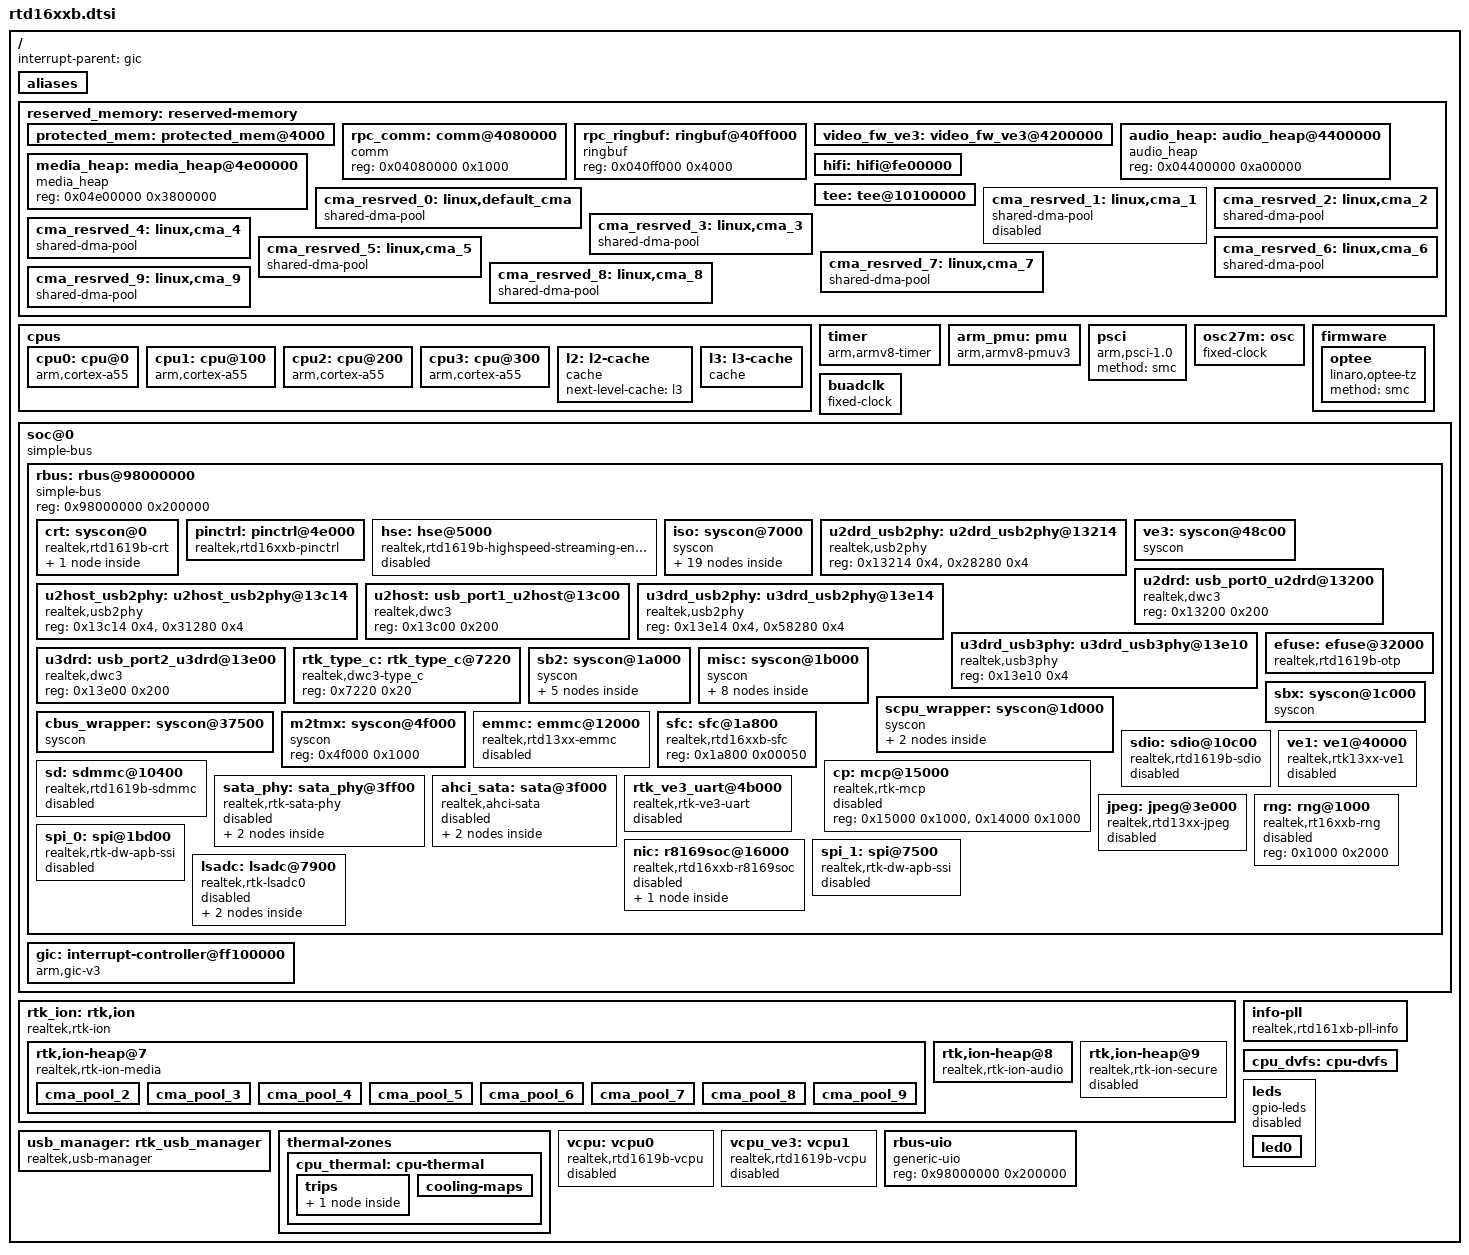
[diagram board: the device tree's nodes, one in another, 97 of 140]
// SPDX-License-Identifier: (GPL-2.0-or-later OR BSD-2-Clause)
/*
 * Realtek RTD1619b SoC family
 *
 * Copyright (c) 2020 Realtek Semiconductor Corp.
 */

#include <dt-bindings/interrupt-controller/arm-gic.h>
#include <dt-bindings/interrupt-controller/irq.h>
#include <dt-bindings/gpio/gpio.h>
#include <dt-bindings/clock/rtd1619b-clk.h>
#include <dt-bindings/reset/rtd1619b-reset.h>
#include <dt-bindings/power/rtd1619b-power.h>
#include <dt-bindings/soc/realtek,mem-flag.h>
#include <dt-bindings/leds/common.h>

/ {
	interrupt-parent = <&gic>;
	#address-cells = <1>;
	#size-cells = <1>;

	aliases {
		serial0 = &uart0;
		serial1 = &uart1;
		serial2 = &uart2;
		i2c0 = &i2c_0;
		i2c1 = &i2c_1;
		i2c3 = &i2c_3;
		i2c4 = &i2c_4;
		i2c5 = &i2c_5;
		watchdog0 = &watchdog;
	};

	reserved_memory: reserved-memory {
		#address-cells = <1>;
		#size-cells = <1>;
		ranges;

		protected_mem: protected_mem@4000 {
			reg = <0x00004000 0x1000000>;
			no-map;
		};

		rpc_comm: comm@4080000 {
			compatible = "comm";
			reg = <0x04080000 0x1000>;
		};

		rpc_ringbuf: ringbuf@40ff000 {
			compatible = "ringbuf";
			reg = <0x040ff000 0x4000>;
		};

		video_fw_ve3: video_fw_ve3@4200000 {
			reg = <0x04200000 0x200000>;
			no-map;
		};

		audio_heap: audio_heap@4400000 {
			compatible = "audio_heap";
			reg = <0x04400000 0xa00000>;
		};

		media_heap: media_heap@4e00000 {
			compatible = "media_heap";
			reg = <0x04e00000 0x3800000>;
		};

		hifi: hifi@fe00000 {
			reg = <0x0fe00000 0x200000>;
			no-map;
		};

		tee: tee@10100000 {
			reg = <0x11000000 0x03200000>;
			no-map;
		};

		cma_resrved_0:linux,default_cma {
			compatible = "shared-dma-pool";
			size = <0x02000000>;
			alignment = <0x01000000>;
			linux,cma-default;
			linux,contiguous-region;
			reusable;
		};

		cma_resrved_1:linux,cma_1 {
			compatible = "shared-dma-pool";
			size = <0x02000000>;
			alloc-ranges=<0x14200000 0x0be00000>;
			linux,contiguous-region;
			reusable;
			status = "disabled";
		};

		cma_resrved_2:linux,cma_2 {
			compatible = "shared-dma-pool";
			size = <0x08000000>;
			alloc-ranges=<0x00000000 0x60000000>;
			linux,contiguous-region;
			reusable;
		};

		cma_resrved_3:linux,cma_3 {
			compatible = "shared-dma-pool";
			size = <0x10000000>;
			alignment = <0x01000000>;
			linux,contiguous-region;
			reusable;
		};

		cma_resrved_4:linux,cma_4 {
			compatible = "shared-dma-pool";
			size = <0x02000000>;
			alignment = <0x01000000>;
			linux,contiguous-region;
			reusable;
		};

		cma_resrved_5:linux,cma_5 {
			compatible = "shared-dma-pool";
			size = <0x01000000>;
			alignment = <0x01000000>;
			alloc-ranges=<0x00000000 0x60000000>;
			linux,contiguous-region;
			reusable;
		};

		cma_resrved_6:linux,cma_6 {
			compatible = "shared-dma-pool";
			size = <0x02000000>;
			alignment = <0x01000000>;
			alloc-ranges=<0x00000000 0x60000000>;
			linux,contiguous-region;
			reusable;
		};

		cma_resrved_7:linux,cma_7 {
			compatible = "shared-dma-pool";
			size = <0x01000000>;
			alignment = <0x01000000>;
			alloc-ranges=<0x00000000 0x60000000>;
			linux,contiguous-region;
			reusable;
		};

		cma_resrved_8:linux,cma_8 {
			compatible = "shared-dma-pool";
			size = <0x06000000>;
			alignment = <0x01000000>;
			alloc-ranges=<0x00000000 0x60000000>;
			linux,contiguous-region;
			reusable;
		};

		cma_resrved_9:linux,cma_9 {
			compatible = "shared-dma-pool";
			reusable;
			size = <0x04000000>;
			alignment = <0x01000000>;
			linux,contiguous-region;
			alloc-ranges=<0x00000000 0x60000000>;
		};
	};

	cpus {
		#address-cells = <1>;
		#size-cells = <0>;

		cpu0: cpu@0 {
			device_type = "cpu";
			compatible = "arm,cortex-a55";
			reg = <0x0>;
			enable-method = "psci";
			next-level-cache = <&l2>;
		};

		cpu1: cpu@100 {
			device_type = "cpu";
			compatible = "arm,cortex-a55";
			reg = <0x100>;
			enable-method = "psci";
			next-level-cache = <&l2>;
		};

		cpu2: cpu@200 {
			device_type = "cpu";
			compatible = "arm,cortex-a55";
			reg = <0x200>;
			enable-method = "psci";
			next-level-cache = <&l2>;
		};

		cpu3: cpu@300 {
			device_type = "cpu";
			compatible = "arm,cortex-a55";
			reg = <0x300>;
			enable-method = "psci";
			next-level-cache = <&l2>;
		};

		l2: l2-cache {
			compatible = "cache";
			next-level-cache = <&l3>;

		};

		l3: l3-cache {
			compatible = "cache";
		};
	};

	timer {
		compatible = "arm,armv8-timer";
		interrupts = <GIC_PPI 13 IRQ_TYPE_LEVEL_LOW>,
			     <GIC_PPI 14 IRQ_TYPE_LEVEL_LOW>,
			     <GIC_PPI 11 IRQ_TYPE_LEVEL_LOW>,
			     <GIC_PPI 10 IRQ_TYPE_LEVEL_LOW>,
			     <GIC_PPI 9 IRQ_TYPE_LEVEL_LOW>;
	};

	arm_pmu: pmu {
		compatible = "arm,armv8-pmuv3";
		interrupts = <GIC_PPI 7 IRQ_TYPE_LEVEL_LOW>;
		interrupt-affinity = <&cpu0>, <&cpu1>, <&cpu2>, <&cpu3>;
	};

	psci: psci {
		compatible = "arm,psci-1.0";
		method = "smc";
	};

	osc27m: osc {
		compatible = "fixed-clock";
		clock-frequency = <27000000>;
		clock-output-names = "osc27m";
		#clock-cells = <0>;
	};

	firmware {
		optee {
			compatible = "linaro,optee-tz";
			method = "smc";
		};
	};

	buadclk: buadclk {
		compatible = "fixed-clock";
		#clock-cells = <0>;
		clock-frequency = <432000000>;
		clock-output-names = "buadclk";
	};

	soc@0 {
		compatible = "simple-bus";
		#address-cells = <1>;
		#size-cells = <1>;
		ranges = <0x00000000 0x00000000 0x00040000>, /* boot code */
			 <0xff100000 0xff100000 0x00200000>, /* GIC */
			 <0x00040000 0x00040000 0x00020000>, /* PCIE IO*/
			 <0xA0000000 0xA0000000 0x00200000>, /* PCIE*/
			 <0x98000000 0x98000000 0x00200000>; /* rbus */

		rbus: rbus@98000000 {
			compatible = "simple-bus";
			reg = <0x98000000 0x200000>;
			#address-cells = <1>;
			#size-cells = <1>;
			ranges = <0x0 0x98000000 0x200000>,
				<0x10040000 0x00040000 0x00020000>, /* PCIE IO*/
				<0xA0000000 0xA0000000 0x00200000>; /* PCIE*/

			crt: syscon@0 {
				compatible = "realtek,rtd1619b-crt", "syscon", "simple-mfd";
				reg = <0x0 0x1000>;
				reg-io-width = <4>;
				#address-cells = <1>;
				#size-cells = <1>;
				ranges = <0x0 0x0 0x1000>;
			};

			pinctrl: pinctrl@4e000 {
				compatible = "realtek,rtd16xxb-pinctrl", "syscon";
				reg = <0x4e000 0x130>;
				reg-io-width = <4>;
				#address-cells = <1>;
				#size-cells = <1>;
				#gpio-range-cells = <3>;
				ranges = <0x0 0x4e000 0x130>;
			};

			hse: hse@5000 {
				reg = <0x5000 0x1000>;
				compatible = "realtek,rtd1619b-highspeed-streaming-engine";
				interrupts = <GIC_SPI 27 4>;
				clocks = <&cc RTD1619B_CRT_CLK_EN_HSE>;
				engine-1-enabled;
				engine-0-disabled;
				status = "disabled";
			};

			iso: syscon@7000 {
				compatible = "syscon", "simple-mfd";
				reg = <0x7000 0x1000>;
				reg-io-width = <4>;
				#address-cells = <1>;
				#size-cells = <1>;
				ranges = <0x0 0x7000 0x1000>;
			};

			u2drd_usb2phy: u2drd_usb2phy@13214 {
				compatible = "realtek,usb2phy";
				reg = <0x13214 0x4>, <0x28280 0x4>;
				#address-cells = <1>;
				#size-cells = <1>;
				ranges;
			};

			ve3: syscon@48c00 {
				compatible = "syscon", "simple-mfd";
				reg = <0x48c00 0x100>;
				reg-io-width = <4>;
				#address-cells = <1>;
				#size-cells = <1>;
				ranges = <0x0 0x48c00 0x100>;
			};

			u2drd: usb_port0_u2drd@13200 {
				compatible = "realtek,dwc3";
				reg = <0x13200 0x200>;
				#address-cells = <1>;
				#size-cells = <1>;
				ranges;
			};

			u2host_usb2phy: u2host_usb2phy@13c14 {
				compatible = "realtek,usb2phy";
				reg = <0x13c14 0x4>, <0x31280 0x4>;
				#address-cells = <1>;
				#size-cells = <1>;
				ranges;
			};

			u2host: usb_port1_u2host@13c00 {
				compatible = "realtek,dwc3";
				reg = <0x13c00 0x200>;
				#address-cells = <1>;
				#size-cells = <1>;
				ranges;
			};

			u3drd_usb2phy: u3drd_usb2phy@13e14 {
				compatible = "realtek,usb2phy";
				reg = <0x13e14 0x4>, <0x58280 0x4>;
				#address-cells = <1>;
				#size-cells = <1>;
				ranges;
			};

			u3drd_usb3phy: u3drd_usb3phy@13e10 {
				compatible = "realtek,usb3phy";
				reg = <0x13e10 0x4>;
				#address-cells = <1>;
				#size-cells = <1>;
				ranges;
			};

			u3drd: usb_port2_u3drd@13e00 {
				compatible = "realtek,dwc3";
				reg = <0x13e00 0x200>;
				#address-cells = <1>;
				#size-cells = <1>;
				ranges;
			};

			rtk_type_c: rtk_type_c@7220 {
				compatible = "realtek,dwc3-type_c";
				reg = <0x7220 0x20>;
				#address-cells = <1>;
				#size-cells = <1>;
				ranges;
			};

			efuse: efuse@32000 {
				compatible = "realtek,rtd1619b-otp";
				reg = <0x32000 0x1000>, <0x17800 0x400>;
				#address-cells = <1>;
				#size-cells = <1>;
				read-only;
			};

			sb2: syscon@1a000 {
				compatible = "syscon", "simple-mfd";
				reg = <0x1a000 0x1000>;
				reg-io-width = <4>;
				#address-cells = <1>;
				#size-cells = <1>;
				ranges = <0x0 0x1a000 0x1000>;
			};

			misc: syscon@1b000 {
				compatible = "syscon", "simple-mfd";
				reg = <0x1b000 0x1000>;
				reg-io-width = <4>;
				#address-cells = <1>;
				#size-cells = <1>;
				ranges = <0x0 0x1b000 0x1000>;
			};

			sbx: syscon@1c000 {
				compatible = "syscon", "simple-mfd";
				reg = <0x1c000 0x1000>;
				reg-io-width = <4>;
				#address-cells = <1>;
				#size-cells = <1>;
				ranges = <0x0 0x1c000 0x1000>;
			};

			scpu_wrapper: syscon@1d000 {
				compatible = "syscon", "simple-mfd", "realtek,rtd1619b-scpu-wrapper";
				reg = <0x1d000 0x1000>;
				reg-io-width = <4>;
				#address-cells = <1>;
				#size-cells = <1>;
				ranges = <0x0 0x1d000 0x1000>;
			};

			cbus_wrapper: syscon@37500 {
				compatible = "syscon", "simple-mfd";
				reg = <0x37500 0x10>;
				reg-io-width = <4>;
				#address-cells = <1>;
				#size-cells = <1>;
				ranges = <0x0 0x37500 0x10>;
			};

			m2tmx: syscon@4f000 {
				compatible = "syscon", "simple-mfd";
				reg = <0x4f000 0x1000>;
				#address-cells = <1>;
				#size-cells = <1>;
				ranges = <0x0 0x4f000 0x1000>;
			};

			emmc: emmc@12000 {
				compatible = "realtek,rtd13xx-emmc";
				emmc-pon-gpios = <&gpio 20 GPIO_ACTIVE_HIGH>;
				emmc-pon-toggle-gpios = <&gpio 18 GPIO_ACTIVE_HIGH>;
				reg = <0x00012000 0x00a00>, /* eMMC */
				      <0x00000000 0x00600>, /* CRT */
				      <0x0001a000 0x00080>, /* SB2 */
				      <0x0004e000 0x00100>, /* ISO */
				      <0x00007e00 0x00020>,
				      <0x0004f000 0x00100>, /* m2tmx */
				      <0x00012180 0x00060>,
				      <0x0000765c 0x00004>;
				reg-names = "emmc","crt","sb2","mux","iso","m2tmx","cqhci","norst";
				interrupts = <0 42 4>;
				speed-step = <3>; /* 0: sdr50, 1: ddr50, 2: hs200, 3: hs400 */
				clocks = <&cc RTD1619B_CRT_CLK_EN_EMMC>,
					 <&cc RTD1619B_CRT_CLK_EN_EMMC_IP>;
				clock-names = "emmc", "emmc_ip";
				resets = <&cc RTD1619B_CRT_RSTN_EMMC>;
				nvmem-cells = <&otp_uuid>;
				nvmem-cell-names = "uuid";
				reset-names = "emmc";
				pddrive_nf_s0 = <1 0x0 0x0 0x0 0x0>; /* pddrive_nf0, pddrive_nf1, pddrive_nf2, pddrive_nf3, pddrive_nf4 ; for sdr50 */
				pddrive_nf_s1 = <1 0x0 0x0 0x0 0x0>; /* pddrive_nf0, pddrive_nf1, pddrive_nf2, pddrive_nf3, pddrive_nf4 ; for ddr50 */
				pddrive_nf_s2 = <1 0x2 0x2 0x2 0x0>; /* pddrive_nf0, pddrive_nf1, pddrive_nf2, pddrive_nf3, pddrive_nf4 ; for hs200 */
				pddrive_nf_s3 = <1 0x4 0x4 0x4 0x0>; /* pddrive_nf0, pddrive_nf1, pddrive_nf2, pddrive_nf3, pddrive_nf4 ; for hs400 */
				phase_tuning = <1 1>; /* arg0: tx tuning switch, arg1: rx tuning switch, if we want to set user defined tx or rx, we should set 0 for tx or rx*/
				reference_phase = <0 0x0 0 0x0>; /* arg0: switch user defined tx, arg1: tx reference phase value, arg2: switch user defined rx, arg3: rx reference phase value*/
				dqs_tuning = <1>;
				dqs_dly_tape = <0x0>;
				mbr_tuning_addr = <0xa31000>;
				hs400_force_tuning = <0x0>;
				cmdq = <0x1>;
				frequency = <0xa6>;
				status = "disabled";
			};

			sfc: sfc@1a800 {
				compatible = "realtek,rtd16xxb-sfc";
				reg = <0x1a800 0x00050>;
				status = "okay";
			};

			sdio: sdio@10c00 {
				compatible = "realtek,rtd1619b-sdio";
				reg = <0x10c00 0x200>,
				      <0x00000 0x200000>;
				interrupts = <GIC_SPI 45 IRQ_TYPE_LEVEL_HIGH>;
				sdio-gpios = <&gpio 3 GPIO_ACTIVE_HIGH>;
				pinctrl-names = "default";
				pinctrl-0 = <&sdio_pins_1>;
				clocks = <&cc RTD1619B_CRT_CLK_EN_SDIO>,
					 <&cc RTD1619B_CRT_CLK_EN_SDIO_IP>;
				clock-names = "sdio", "sdio_ip";
				resets = <&cc RTD1619B_CRT_RSTN_SDIO>;
				status = "disabled";
			};

			sd: sdmmc@10400 {
				compatible = "realtek,rtd1619b-sdmmc";
				reg = <0x10400 0x200>, /* SDMMC */
				      <0x00000 0x400>, /* CRT */
				      <0x1A000 0x400>, /* BS2 */
				      <0x4E000 0x60>, /* ISO */
				      <0x10A00 0x40>, /* SDIO */
				      <0x07000 0x200>;
				interrupts = <GIC_SPI 44 IRQ_TYPE_LEVEL_HIGH>;
				sd-power-gpios = <&gpio 30 GPIO_ACTIVE_HIGH>; /*sd power , output, default high  (poweroff) */
				sd-wp-gpios = <&gpio 34 GPIO_PULL_UP>;
				sd-cd-gpios = <&gpio 35 GPIO_PULL_UP>;
				sdmmc-bounce = <1>;
				pinctrl-names = "default";
				pinctrl-0 = <&sdcard_pins_low>,
				            <&scpu_ejtag_pins_disable>;
				clocks = <&cc RTD1619B_CRT_CLK_EN_SD>,
				         <&cc RTD1619B_CRT_CLK_EN_SD_IP>;
				clock-names = "sd", "sd_ip";
				resets = <&cc RTD1619B_CRT_RSTN_SD>;
				status = "disabled";
			};

			cp: mcp@15000 {
				compatible = "realtek,rtk-mcp", "syscon";
				reg = <0x15000 0x1000>,
				      <0x14000 0x1000>;
				status = "disabled";
			};

			sata_phy: sata_phy@3ff00 {
				compatible = "realtek,rtk-sata-phy", "syscon";
				reg = <0x3ff00 0x100>;
				clocks = <&cc RTD1619B_CRT_CLK_EN_SATA_WRAP_SYS>,
					 <&cc RTD1619B_CRT_CLK_EN_SATA_WRAP_SYSH>;
				clock-names = "wrap_sys", "wrap_sysh";
				resets = <&cc RTD1619B_CRT_RSTN_SATA_WRAP>;
				realtek,crt = <&crt>;
				realtek,phyctl = <&m2tmx>;
				nvmem-cells = <&otp_sata_cal>;
				nvmem-cell-names = "sata-cal";
				#address-cells = <1>;
				#size-cells = <0>;
				#phy-cells = <1>;
				status = "disabled";
			};

			ahci_sata: sata@3f000 {
				compatible = "realtek,ahci-sata";
				reg = <0x3f000 0xf00>;
				interrupts = <GIC_SPI 49 IRQ_TYPE_LEVEL_HIGH>;
				clocks = <&cc RTD1619B_CRT_CLK_EN_SATA_MAC_SYSH>;
				resets = <&cc RTD1619B_CRT_RSTN_SATA_MAC_COM>;
				realtek,satawrap = <&sata_phy>;
				#address-cells = <1>;
				#size-cells = <0>;
				status = "disabled";
			};

			rtk_ve3_uart@4b000 {
				compatible = "realtek,rtk-ve3-uart";
				reg = <0x4b000 0x20>;
				clocks = <&cc RTD1619B_CRT_CLK_VE3>;
				clock-names = "ve3";
				log_enable = <0>;
				status = "disabled";
			};

			ve1: ve1@40000 {
				compatible = "realtek,rtk13xx-ve1";
				reg = <0x40000 0xc000>,
				      <0x08000 0x1000>,
				      <0x07000 0x30>,
				      <0x0e000 0x1000>;
				interrupts = <GIC_SPI 53 IRQ_TYPE_LEVEL_HIGH>,
					     <GIC_SPI 55 IRQ_TYPE_LEVEL_HIGH>;
				power-domains = <&pd RTD1619B_PD_VE1>;
				clocks = <&cc RTD1619B_CRT_CLK_VE1>;
				resets = <&cc RTD1619B_CRT_RSTN_VE1>,
					 <&cc RTD1619B_CRT_RSTN_VE1_BIST>;
				reset-names = "reset","bist";
				assigned-clocks = <&cc RTD1619B_CRT_CLK_VE1>;
				assigned-clock-parents = <&cc RTD1619B_CRT_PLL_VE1>;
				status = "disabled";
			};

			jpeg: jpeg@3e000 {
				compatible = "realtek,rtd13xx-jpeg";
				reg = <0x3e000 0x1000>,
				      <0x07000 0x30>;
				interrupts = <GIC_SPI 52 IRQ_TYPE_LEVEL_HIGH>;
				clocks = <&cc RTD1619B_CRT_CLK_EN_JPEG>;
				clock-names = "jpeg";
				resets = <&cc RTD1619B_CRT_RSTN_JPEG>;
				status = "disabled";
			};

			rng: rng@1000 {
				compatible = "realtek,rt16xxb-rng";
				reg = <0x1000 0x2000>;
				status = "disabled";
			};

			nic: r8169soc@16000 {
				compatible = "realtek,rtd16xxb-r8169soc";
				reg = <0x16000 0x1000>;   /* ETN */
				realtek,iso = <&iso>;
				realtek,pinctrl = <&pinctrl>;
				interrupts = <0 22 4>;
				pinctrl-names = "default";
				pinctrl-0 = <&etn_led_pins>;
				local-mac-address = [00 10 20 30 40 50];
				wol-enable = <0>;
				output-mode = <0>; /* 0:embedded PHY */
				acp = <0>; /* 0: disable */
				eee = <1>; /* 0: disable, 1: enable */
				clocks = <&ic RTD1619B_ISO_CLK_EN_ETN_250M>,
					 <&ic RTD1619B_ISO_CLK_EN_ETN_SYS>;
				clock-names = "etn_250m",
					      "etn_sys";
				resets = <&ic RTD1619B_ISO_RSTN_GMAC>,
					 <&ic RTD1619B_ISO_RSTN_GPHY>;
				reset-names = "gmac",
					      "gphy";
				nvmem-cells = <&otp_etn_rc_r_amp_cal>;
				nvmem-cell-names = "rc_r_amp_cal";
				status = "disabled";

				phy_0 {
					interrupt-parent = <&iso_irq_mux>;
					interrupts = <28>, <29>, <30>;
					irq-mask = <0x70000000>;
					por-xv-mask = <0x00000111>;
				};
			};

			spi_0: spi@1bd00 {
				compatible = "realtek,rtk-dw-apb-ssi";
				#address-cells = <1>;
				#size-cells = <0>;
				interrupt-parent = <&misc_irq_mux>;
				interrupts = <27>; /* SPI_INT */
				reg = <0x1bd00 0x100>, /* DW SPI */
				      <0x1b300 0x18>; /* SPI wrapper */
				pinctrl-names = "default";
				pinctrl-0 = <&gspi_pins_0>;
				num-chipselect = <1>;
				bus-num = <0>;
				clocks = <&cc RTD1619B_CRT_CLK_EN_GSPI>;
				clock-frequency = <256000000>;
				resets = <&cc RTD1619B_CRT_RSTN_GSPI>;
				status = "disabled";
			};

			spi_1: spi@7500 {
				compatible = "realtek,rtk-dw-apb-ssi";
				#address-cells = <1>;
				#size-cells = <0>;
				interrupt-parent = <&iso_irq_mux>;
				interrupts = <6>; /* SPI1_INT */
				reg = <0x7500 0x100>, /* DW SPI */
				      <0x72e4 0x1c>; /* SPI wrapper */
				pinctrl-names = "default";
				pinctrl-0 = <&iso_gspi_pins_0>;
				num-chipselect = <1>;
				bus-num = <0>;
				clock-frequency = <256000000>;
				clocks = <&ic RTD1619B_ISO_CLK_EN_ISO_GSPI>;
				resets = <&ic RTD1619B_ISO_RSTN_ISO_GSPI>;
				status = "disabled";
			};

			lsadc: lsadc@7900 {
				compatible = "realtek,rtk-lsadc0";
				interrupt-parent =  <&iso_irq_mux>;
				interrupts = <3>; /* LSADC0_INT */
				reg = <0x7900 0x200>, /* LSADC */
				      <0x34c 0x4>; /* LSADC_PG */
				clk_gating_en = <1>; /* LSADC0 0:disable; 1:enable */
				debounce0_cnt = <8>; /* debounce cnt : 0 ~ 15 */
				clocks = <&ic RTD1619B_ISO_CLK_EN_LSADC>;
				resets = <&ic RTD1619B_ISO_RSTN_LSADC>;
				status = "disabled";

				lsadc0-pad0 {
					activate = <1>; /* 0:in-activate; 1:activate */
					ctrl_mode = <0>; /* 0:Voltage mode; 1:Current mode*/
					sw_idx = <0>; /* 0:External input pin 0; 1:External input pin 1 */
					voltage_threshold = <4>; /* 8 bits : 0 ~ 255 */
					adc_val_baseline = <255>; /* 8 bits : 0 ~ 255 */
				};

				lsadc0-pad1 {
					activate = <1>; /* 0:in-activate; 1:activate */
					ctrl_mode = <0>; /* 0:Voltage mode; 1:Current mode*/
					sw_idx = <1>; /* 0:External input pin 0; 1:External input pin 1 */
					voltage_threshold = <255>; /* 8 bits : 0 ~ 255 */
					adc_val_baseline = <255>; /* 8 bits : 0 ~ 255 */
				};
			};
		};

		gic: interrupt-controller@ff100000 {
			compatible = "arm,gic-v3";
			#address-cells = <1>;
			#size-cells = <1>;
			reg = <0xff100000 0x10000>,
			      <0xff140000 0x80000>;
			interrupts = <GIC_PPI 9 IRQ_TYPE_LEVEL_HIGH>;
			interrupt-controller;
			#interrupt-cells = <3>;
		};
	};

	rtk_ion:rtk,ion {
		compatible = "realtek,rtk-ion";
		#address-cells = <1>;
		#size-cells = <0>;

		rtk,ion-heap@7 { /* Media */
			compatible = "realtek,rtk-ion-media";
			reg = <7>;
			memory-region = <&media_heap>;
			rtk,use-cma-pools;
			/* rtk,cma-pools-skip-dma-default-array; */
			rtk,cma-pool-flags = <RTK_FLAG_CMA_POOL>;
			rtk,cma-pool-extFlags-info = <RTK_FLAG_VCPU_FWACC 0x00000000 0x60000000
						      RTK_FLAG_ACPUACC 0x00000000 0x60000000
						      RTK_FLAG_HWIPACC 0x00000000 0x80000000>;
			rtk,memory-reserve = <0x04e00000 0x3800000 RTK_FLAG_ION_HEAP
					      0x00C40000 0x003C4000 RTK_FLAG_PROTECTED_DYNAMIC_METADATA>;

			rtk,flag-replace-table = <(RTK_FLAG_PROTECTED_V2_FW_STACK) (RTK_FLAG_PROTECTED_V2_AUDIO_POOL | RTK_FLAG_PROTECTED_EXT_BITS(1))
						  (RTK_FLAG_PROTECTED_V2_VIDEO_POOL) (RTK_FLAG_PROTECTED_V2_VIDEO_POOL | RTK_FLAG_PROTECTED_EXT_BITS(1))>;

			rtk,pre-alloc = <(RTK_FLAG_PROTECTED_V2_AUDIO_POOL | RTK_FLAG_PROTECTED_EXT_BITS(1) | RTK_FLAG_ACPUACC) (0x00a00000)>;

			cma_pool_2 {
				memory-region = <&cma_resrved_2>;
				rtk,cma-pool-extFlags = <RTK_FLAG_PROTECTED_DYNAMIC_VO>;
			};

			cma_pool_3 {
				memory-region = <&cma_resrved_3>;
				rtk,cma-pool-extFlags = <RTK_FLAG_PROTECTED_DYNAMIC_VO>;
			};

			cma_pool_4 {
				memory-region = <&cma_resrved_4>;
				rtk,cma-pool-extFlags = <RTK_FLAG_PROTECTED_V2_TP_POOL>;
			};

			cma_pool_5 {
				memory-region = <&cma_resrved_5>;
				rtk,cma-pool-extFlags = <RTK_FLAG_PROTECTED_V2_AUDIO_POOL>;
			};

			cma_pool_6 {
				memory-region = <&cma_resrved_6>;
				rtk,cma-pool-extFlags = <RTK_FLAG_PROTECTED_V2_VIDEO_POOL>;
			};

			cma_pool_7 {
				memory-region = <&cma_resrved_7>;
				rtk,cma-pool-extFlags = <RTK_FLAG_PROTECTED_V2_AO_POOL>;
			};

			cma_pool_8 {
				memory-region = <&cma_resrved_8>;
				rtk,cma-pool-extFlags = <RTK_FLAG_PROTECTED_V2_VIDEO_POOL>;
			};

			cma_pool_9 {
				memory-region = <&cma_resrved_9>;
				rtk,cma-pool-extFlags = <RTK_FLAG_PROTECTED_DYNAMIC_OTA>;
			};
		};

		rtk,ion-heap@8 { /* Audio */
			compatible = "realtek,rtk-ion-audio";
			reg = <8>;
			memory-region = <&audio_heap>;
			rtk,memory-reserve = <0x04400000
					      0x00a00000
					      RTK_FLAG_ION_HEAP>;
		};

		rtk,ion-heap@9 { /* Secure */
			compatible = "realtek,rtk-ion-secure";
			reg = <9>;
			rtk,memory-reserve = <>;
			status = "disabled";
		};
	};

	info-pll {
		compatible = "realtek,rtd161xb-pll-info";
		realtek,crt = <&crt>;
		realtek,scpu-wrapper = <&scpu_wrapper>;
	};

	usb_manager: rtk_usb_manager {
		compatible = "realtek,usb-manager";
	};

	cpu_dvfs: cpu-dvfs {
	};

	thermal-zones {
		cpu_thermal: cpu-thermal {
			polling-delay-passive = <250>;
			polling-delay = <1000>;
			thermal-sensors = <&cpu_tm>;
			trips {
				cpu_crit: cpu-crit {
					temperature = <120000>;
					hysteresis = <0>;
					type = "critical";
				};
			};
			cooling-maps {
			};
		};
	};

	leds: leds {
		compatible = "gpio-leds";
		status = "disabled";
		led0 {
			gpios = <&gpio 7 GPIO_PULL_DOWN>;
			linux,default-trigger = "disk-activity";
			function = LED_FUNCTION_DISK;
		};
	};

	vcpu: vcpu0 {
		compatible = "realtek,rtd1619b-vcpu";
		power-domains = <&pd RTD1619B_PD_VE2>;
		clocks = <&cc RTD1619B_CRT_CLK_VE2>;
		resets = <&cc RTD1619B_CRT_RSTN_VE2>, <&cc RTD1619B_CRT_RSTN_VE2_BIST>;
		reset-names = "reset","bist";
		status = "disabled";
	};

	vcpu_ve3: vcpu1 {
		compatible = "realtek,rtd1619b-vcpu";
		power-domains = <&pd RTD1619B_PD_VE3>;
		clocks = <&cc RTD1619B_CRT_CLK_VE3>;
		status = "disabled";
	};
	rbus-uio {
		reg = <0x98000000 0x200000>;
		compatible = "generic-uio";
	};
};

&crt {
	cc: clock-controller {
		compatible = "realtek,rtd1619b-crt-clk";
		#clock-cells = <1>;
		#reset-cells = <1>;
		realtek,sb2-lock = <&sb2_lock0>;

		assigned-clocks = <&cc RTD1619B_CRT_PLL_SCPU>;
		assigned-clock-rates = <1600000000>;
	};
};

&iso {
	ic: clock-controller {
		compatible = "realtek,rtd1619b-iso-clk";
		#clock-cells = <1>;
		#reset-cells = <1>;
	};

	pd: power-domain {
		compatible = "realtek,rtd1619b-power";
		#power-domain-cells = <1>;
	};

	iso_irq_mux: iso_irq_mux {
		compatible = "realtek,rtd16xxb-iso-irq-mux";
		syscon = <&iso>;
		interrupts-extended = <&gic GIC_SPI 41 IRQ_TYPE_LEVEL_HIGH>,
				      <&gic GIC_SPI 0 IRQ_TYPE_LEVEL_HIGH>;
		interrupt-controller;
		#address-cells = <0>;
		#interrupt-cells = <1>;
	};

	uart0: serial0@800 {
		compatible = "snps,dw-apb-uart";
		reg = <0x800 0x400>;
		reg-shift = <2>;
		reg-io-width = <4>;
		interrupts = <GIC_SPI 68 IRQ_TYPE_LEVEL_HIGH>;
		clock-frequency = <432000000>;
		clock-names = "buadclk", "apb_pclk";
		clocks = <&buadclk>, <&ic RTD1619B_ISO_CLK_EN_MISC_UR0>;
		resets = <&ic RTD1619B_ISO_RSTN_UR0>;
		status = "disabled";
	};

	gpio: gpio@100 {
		compatible = "realtek,gpio";
		reg = <0x100 0x100>,
			<0x0 0xB0>;
		syscon = <&iso>;
		realtek,gpio_base = <0>;
		realtek,gpio_numbers = <82>;
		interrupt-parent = <&iso_irq_mux>;
		#address-cells = <0>;
		#interrupt-cells = <1>;
		interrupt-controller;
		interrupts = <19>, <20>;
		gpio-ranges = <&pinctrl 0 0 82>;
		gpio-controller;
		#gpio-cells = <2>;
		status = "disabled";
	};
	/*
	 * Set gpio default value need to add gpios & gpio-default
	 * ex:
	 *   gpios = <&gpio 0 GPIO_ACTIVE_HIGH>,
	 *           <&gpio 1 GPIO_ACTIVE_HIGH>,
	 *           <&gpio 2 GPIO_PULL_UP>;
	 *
	 *   gpio-default = <0>, //output low
	 *                  <1>, //output high
	 *                  <2>; //input
	 */
	gpio_default: gpio_default {
		compatible = "realtek,gpio-set-default";
		status = "disabled";
	};

	i2c_0: i2c_0@d00 {
		compatible = "realtek,highspeed-i2c";
		reg = <0xd00 0x100>,
		      <0x000 0x100>;
		interrupt-parent = <&iso_irq_mux>;
		interrupts = <8>;
		pinctrl-names = "default";
		pinctrl-0 = <&i2c_pins_0>;
		#address-cells = <1>;
		#size-cells = <0>;
		clocks = <&ic RTD1619B_ISO_CLK_EN_I2C0>;
		resets = <&ic RTD1619B_ISO_RSTN_I2C_0>;
		status = "disabled";
	};

	i2c_1: i2c_1@c00 {
		compatible = "realtek,i2c";
		reg = <0xc00 0x100>,
		      <0x000 0x100>;
		interrupt-parent = <&iso_irq_mux>;
		interrupts = <11>;
		pinctrl-names = "default";
		pinctrl-0 = <&i2c_pins_1>;
		#address-cells = <1>;
		#size-cells = <0>;
		clocks = <&ic RTD1619B_ISO_CLK_EN_I2C1>;
		resets = <&ic RTD1619B_ISO_RSTN_I2C_1>;
		status = "disabled";
	};

	watchdog: watchdog@a20 {
		compatible = "realtek,watchdog";
		reg = <0xa20 0x10>, <0xa30 0x8>;
		interrupts-extended = <&iso_irq_mux 4>;
		timeout-sec = <20>;
		ov-rstb-oe-init = <1>;
		ov-rstb-oe = <0>;
		status = "disabled";
	};

	watchdog5: watchdog-st@aa0 {
		reg = <0xaa0 0x20>;
		compatible = "realtek,rtd1619b-watchdog-status";
		status = "disabled";
	};

	reboot_mode: reboot-mode@640 {
		compatible = "realtek,reboot-mode";
		reg = <0x640 0x4>;
		status = "disabled";
	};

	rtk_fw_pm: rtk_fw_pm {
		compatible = "realtek,fw_pm";
		status = "disabled";
	};

	rtk_pm: rtk_pm {
		compatible = "realtek,rtd16xxb_pm";
		system-power-controller;
		syscon = <&iso>;
		pm-dbg = <0>;
		status = "disabled";
	};

	rfkill: rfkilligpio {
		compatible = "Realtek,rfkill";
		realtek,iso = <&iso>;
		realtek,pinctrl = <&pinctrl>;
		rfkill-gpios = <&gpio 6 GPIO_ACTIVE_HIGH>; /*bt power, output, default low(poweroff) */
		status = "disabled";
	};

	pwm: pwm@d0 {
		compatible = "realtek,rtk-pwm";
		#pwm-cells = <2>;
		reg = <0xd0 0xc>;
		realtek,iso = <&iso>;
		status = "disabled";

		pwm_0 {
			enable = <0>;
			clkout_div = <0xff>; /* default OCD: from 0x0 to 0xff */
			clksrc_div = <0x1>; /* default OSD: from 0x0 to 0xf */
			duty_rate = <50>; /* default duty_rate 0 ~ 100 */
		};

		pwm_1 {
			enable = <0>;
			clkout_div = <0xff>; /* default OCD: from 0x0 to 0xff */
			clksrc_div = <0x1>; /* default OSD: from 0x0 to 0xf */
			duty_rate = <50>; /* default duty_rate 0 ~ 100 */
		};

		pwm_2 {
			enable = <0>;
			clkout_div = <0xff>; /* default OCD: from 0x0 to 0xff */
			clksrc_div = <0x1>; /* default OSD: from 0x0 to 0xf */
			duty_rate = <50>; /* default duty_rate 0 ~ 100 */
		};

		pwm_3 {
			enable = <0>;
			clkout_div = <0xff>; /* default OCD: from 0x0 to 0xff */
			clksrc_div = <0x1>; /* default OSD: from 0x0 to 0xf */
			duty_rate = <50>; /* default duty_rate 0 ~ 100 */
		};
	};
};

&sb2 {
	chip: chip-info@200 {
		compatible = "realtek,soc-chip";
		reg = <0x200 0x8>;
	};

	rpc: rpc@a80 {
		compatible = "realtek,rpc";
		reg = <0xa80 0xc>; /* interrupt enable */
		syscon = <&ve3>;
		interrupts = <0 33 4>,
			     <0 92 4>,
			     <0 55 4>;
		realtek,refclk = <&refclk>;
	};

	rtk_fb: rtk-fb {
		compatible = "realtek,framebuffer";
		interrupt-parent = <&gic>;
		interrupts = <0 33 4>;
		syscon = <&sb2>;
		buffer-cnt = <3>;
		resolution = <1920 1080>;
		fps = <60>;
		osd-init = <1>;
		skip-front = <2>;
	};

	sb2_lock0: sb2-lock@0 {
		compatible = "realtek,sb2-sem";
		reg = <0x0 0x4>;
	};

	sb2_inv: inv@4 {
		compatible = "realtek,sysbrg2-inv";
		reg = <0x4 0x10>;
		interrupts = <0 36 4>;
		nvmem-cells = <&otp_secure_chip_en>;
		nvmem-cell-names = "secure_en";
		status = "disabled";
	};
};

&misc {
	misc_irq_mux: misc_irq_mux {
		compatible = "realtek,rtd16xxb-misc-irq-mux";
		syscon = <&misc>;
		interrupts-extended = <&gic GIC_SPI 40 IRQ_TYPE_LEVEL_HIGH>,
				      <&gic GIC_SPI 89 IRQ_TYPE_LEVEL_HIGH>,
				      <&gic GIC_SPI 90 IRQ_TYPE_LEVEL_HIGH>;
		interrupt-controller;
		#address-cells = <0>;
		#interrupt-cells = <1>;
	};

	refclk: refclk@538 {
		compatible = "realtek,refclk";
		reg = <0x538 0x10>;
	};

	uart1: serial1@200 {
		compatible = "snps,dw-apb-uart";
		reg = <0x200 0x400>;
		reg-shift = <2>;
		reg-io-width = <4>;
		interrupts-extended = <&misc_irq_mux 3>;
		pinctrl-names = "default";
		pinctrl-0 = <&uart1_pins>;
		clock-frequency = <432000000>;
		clock-names = "buadclk", "apb_pclk";
		clocks = <&buadclk>, <&cc RTD1619B_CRT_CLK_EN_UR1>;
		resets = <&cc RTD1619B_CRT_RSTN_UR1>;
		status = "disabled";
	};

	uart2: serial2@400 {
		compatible = "snps,dw-apb-uart";
		reg = <0x400 0x400>;
		reg-shift = <2>;
		reg-io-width = <4>;
		interrupts-extended = <&misc_irq_mux 7>;
		clock-frequency = <432000000>;
		clock-names = "buadclk", "apb_pclk";
		clocks = <&buadclk>, <&cc RTD1619B_CRT_CLK_EN_UR2>;
		resets = <&cc RTD1619B_CRT_RSTN_UR2>;
		status = "disabled";
	};

	i2c_3: i2c_3@900 {
		compatible = "realtek,i2c";
		reg = <0x900 0x100>,
		      <0x000 0x100>;
		interrupt-parent = <&misc_irq_mux>;
		interrupts = <23>;
		pinctrl-names = "default";
		pinctrl-0 = <&i2c_pins_3>;
		#address-cells = <1>;
		#size-cells = <0>;
		clocks = <&cc RTD1619B_CRT_CLK_EN_MISC_I2C_3>;
		resets = <&cc RTD1619B_CRT_RSTN_I2C_3>;
		status = "disabled";
	};

	i2c_4: i2c_4@a00 {
		compatible = "realtek,i2c";
		reg = <0xa00 0x100>,
		      <0x000 0x100>;
		interrupt-parent = <&misc_irq_mux>;
		interrupts = <15>;
		pinctrl-names = "default";
		pinctrl-0 = <&i2c_pins_4>;
		#address-cells = <1>;
		#size-cells = <0>;
		clocks = <&cc RTD1619B_CRT_CLK_EN_MISC_I2C_4>;
		resets = <&cc RTD1619B_CRT_RSTN_I2C_4>;
		status = "disabled";
	};

	i2c_5: i2c_5@b00 {
		compatible = "realtek,i2c";
		reg = <0xb00 0x100>,
		      <0x000 0x100>;
		interrupt-parent = <&misc_irq_mux>;
		interrupts = <14>;
		pinctrl-names = "default";
		pinctrl-0 = <&i2c_pins_5>;
		#address-cells = <1>;
		#size-cells = <0>;
		clocks = <&cc RTD1619B_CRT_CLK_EN_MISC_I2C_5>;
		resets = <&cc RTD1619B_CRT_RSTN_I2C_5>;
		status = "disabled";
	};

	rtk_fan: rtk_fan@c00 {
		compatible = "realtek,rtk-fan";
		reg = <0xc00 0x14>;
		interrupt-parent = <&misc_irq_mux>;
		interrupts = <29>;
		status = "disable";

		timer_target = <0x100000>;
		fan_debounce = <0x0>;// 0x0~0x7
		fan_factor = <2>; /* count per revolution for fan */
		clocks = <&cc RTD1619B_CRT_CLK_EN_FAN>;
		resets = <&cc RTD1619B_CRT_RSTN_FAN>;
		pinctrl-names = "default";
		pinctrl-0 = <&dc_fan_sensor_pins>;

		/* For speed control */
		pwms = <&pwm 1 37878>; // (1) pwm node (2) pwm id (3) out period_ns (1/26400 ns)
	};
};

&sata_phy {
	sata_phy0: sata-phy@0 {
		reg = <0>;
		resets = <&cc RTD1619B_CRT_RSTN_SATA_MDIO0>,
			 <&cc RTD1619B_CRT_RSTN_SATA_PHY_POW0>;
		status = "disabled";
	};

	sata_phy1: sata-phy@1 {
		reg = <1>;
		resets = <&cc RTD1619B_CRT_RSTN_SATA_MDIO1>,
			 <&cc RTD1619B_CRT_RSTN_SATA_PHY_POW1>;
		status = "disabled";
	};
};

&ahci_sata {
	sata_port0: sata-port@0 {
		reg = <0>;
		phys = <&sata_phy 0>;
		resets = <&cc RTD1619B_CRT_RSTN_SATA_MAC_P0>;
		sata-gpios = <&gpio 80 GPIO_ACTIVE_HIGH>;
		status = "disabled";
	};

	sata_port1: sata-port@1 {
		reg = <1>;
		phys = <&sata_phy 1>;
		resets = <&cc RTD1619B_CRT_RSTN_SATA_MAC_P1>;
		sata-gpios = <&gpio 81 GPIO_ACTIVE_HIGH>;
		status = "disabled";
	};
};

&scpu_wrapper {
	clk-det {
		compatible = "realtek,clk-det";
		clk-det,offset = <0x700>;
		clk-det,type = <1>;
		clock-output-names = "ref_pll_scpu";
	};

	cpu_tm: thermal-sensor@b00 {
		compatible = "realtek,rtd1619b-thermal-sensor";
		reg = <0xb00 0x48>;
		realtek,scpu-wrapper = <&scpu_wrapper>;
		#thermal-sensor-cells = <0>;
		status = "disabled";
	};
};

#include "rtd16xxb-efuse.dtsi"
#include "rtd16xxb-pinctrl.dtsi"
#include "rtd16xxb-usb.dtsi"
#include "rtd16xxb-pcie.dtsi"
